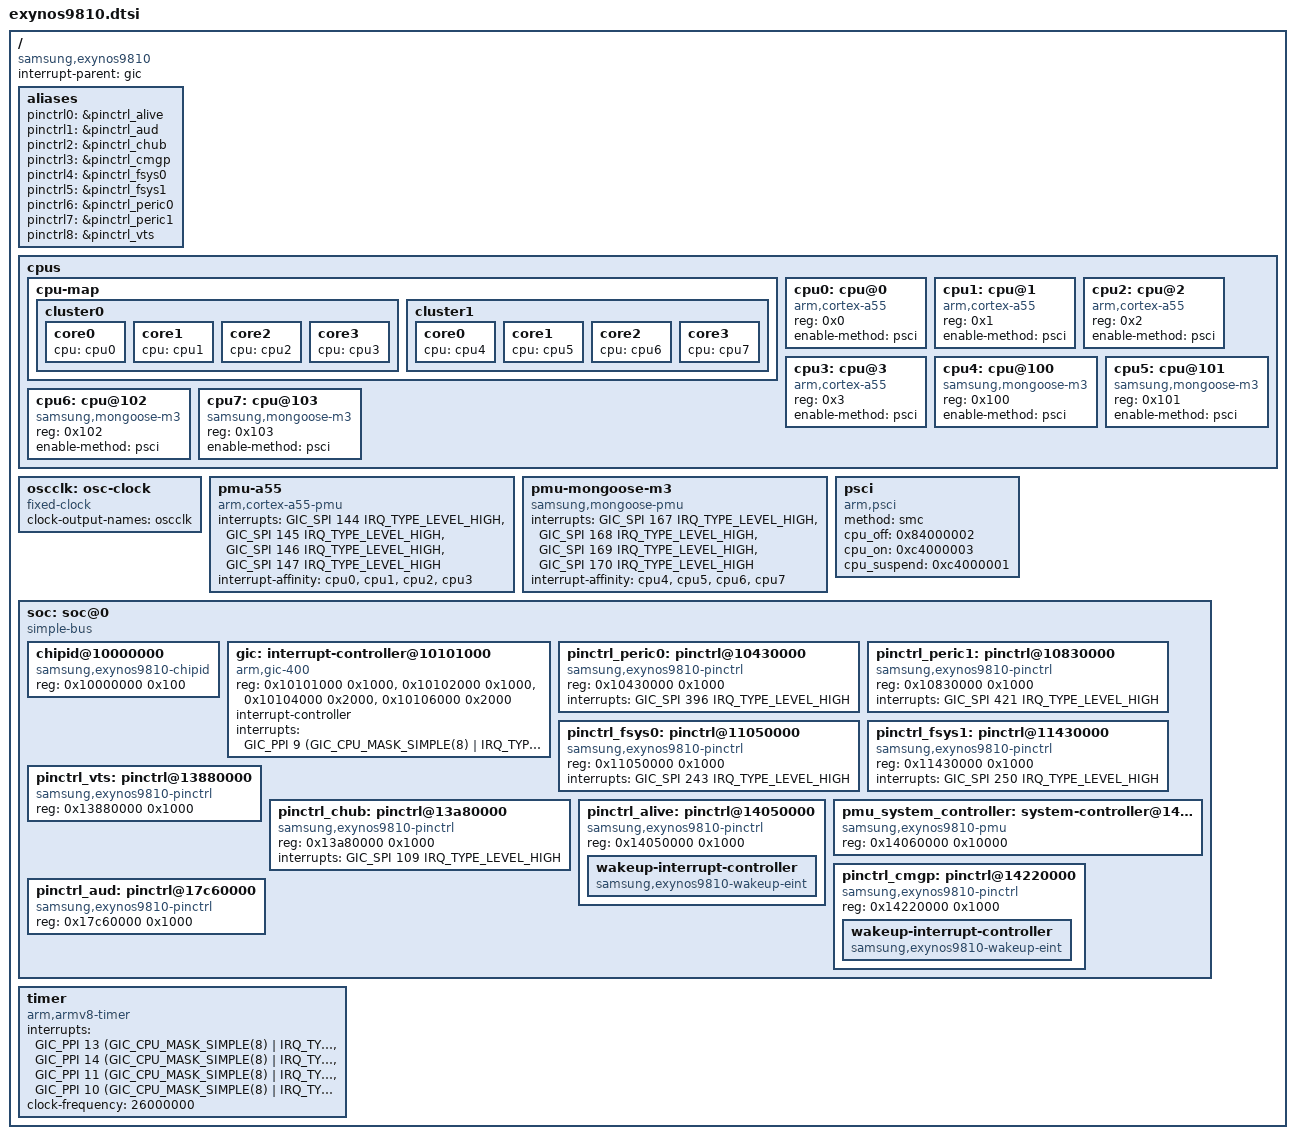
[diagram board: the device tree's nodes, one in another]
// SPDX-License-Identifier: GPL-2.0 OR BSD-3-Clause
/*
 * Samsung Exynos 9810 SoC device tree source
 *
 * Copyright (c) 2024 Markuss Broks <markuss.broks@gmail.com>
 * Copyright (c) 2024 Maksym Holovach <nergzd@nergzd723.xyz>
 */

#include <dt-bindings/interrupt-controller/arm-gic.h>

/ {
	compatible = "samsung,exynos9810";
	#address-cells = <2>;
	#size-cells = <1>;

	interrupt-parent = <&gic>;

	aliases {
		pinctrl0 = &pinctrl_alive;
		pinctrl1 = &pinctrl_aud;
		pinctrl2 = &pinctrl_chub;
		pinctrl3 = &pinctrl_cmgp;
		pinctrl4 = &pinctrl_fsys0;
		pinctrl5 = &pinctrl_fsys1;
		pinctrl6 = &pinctrl_peric0;
		pinctrl7 = &pinctrl_peric1;
		pinctrl8 = &pinctrl_vts;
	};

	cpus {
		#address-cells = <1>;
		#size-cells = <0>;

		cpu-map {
			cluster0 {
				core0 {
					cpu = <&cpu0>;
				};
				core1 {
					cpu = <&cpu1>;
				};
				core2 {
					cpu = <&cpu2>;
				};
				core3 {
					cpu = <&cpu3>;
				};
			};

			cluster1 {
				core0 {
					cpu = <&cpu4>;
				};
				core1 {
					cpu = <&cpu5>;
				};
				core2 {
					cpu = <&cpu6>;
				};
				core3 {
					cpu = <&cpu7>;
				};
			};
		};

		cpu0: cpu@0 {
			device_type = "cpu";
			compatible = "arm,cortex-a55";
			reg = <0x0>;
			enable-method = "psci";
		};

		cpu1: cpu@1 {
			device_type = "cpu";
			compatible = "arm,cortex-a55";
			reg = <0x1>;
			enable-method = "psci";
		};

		cpu2: cpu@2 {
			device_type = "cpu";
			compatible = "arm,cortex-a55";
			reg = <0x2>;
			enable-method = "psci";
		};

		cpu3: cpu@3 {
			device_type = "cpu";
			compatible = "arm,cortex-a55";
			reg = <0x3>;
			enable-method = "psci";
		};

		cpu4: cpu@100 {
			device_type = "cpu";
			compatible = "samsung,mongoose-m3";
			reg = <0x100>;
			enable-method = "psci";
		};

		cpu5: cpu@101 {
			device_type = "cpu";
			compatible = "samsung,mongoose-m3";
			reg = <0x101>;
			enable-method = "psci";
		};

		cpu6: cpu@102 {
			device_type = "cpu";
			compatible = "samsung,mongoose-m3";
			reg = <0x102>;
			enable-method = "psci";
		};

		cpu7: cpu@103 {
			device_type = "cpu";
			compatible = "samsung,mongoose-m3";
			reg = <0x103>;
			enable-method = "psci";
		};
	};

	oscclk: osc-clock {
		compatible = "fixed-clock";
		#clock-cells = <0>;
		clock-output-names = "oscclk";
	};

	pmu-a55 {
		compatible = "arm,cortex-a55-pmu";
		interrupts = <GIC_SPI 144 IRQ_TYPE_LEVEL_HIGH>,
			     <GIC_SPI 145 IRQ_TYPE_LEVEL_HIGH>,
			     <GIC_SPI 146 IRQ_TYPE_LEVEL_HIGH>,
			     <GIC_SPI 147 IRQ_TYPE_LEVEL_HIGH>;
		interrupt-affinity = <&cpu0>,
				     <&cpu1>,
				     <&cpu2>,
				     <&cpu3>;
	};

	pmu-mongoose-m3 {
		compatible = "samsung,mongoose-pmu";
		interrupts = <GIC_SPI 167 IRQ_TYPE_LEVEL_HIGH>,
			     <GIC_SPI 168 IRQ_TYPE_LEVEL_HIGH>,
			     <GIC_SPI 169 IRQ_TYPE_LEVEL_HIGH>,
			     <GIC_SPI 170 IRQ_TYPE_LEVEL_HIGH>;
		interrupt-affinity = <&cpu4>,
				     <&cpu5>,
				     <&cpu6>,
				     <&cpu7>;
	};

	psci {
		compatible = "arm,psci";
		method = "smc";
		cpu_off = <0x84000002>;
		cpu_on = <0xc4000003>;
		cpu_suspend = <0xc4000001>;
	};

	soc: soc@0 {
		compatible = "simple-bus";
		ranges = <0x0 0x0 0x0 0x20000000>;

		#address-cells = <1>;
		#size-cells = <1>;

		chipid@10000000 {
			compatible = "samsung,exynos9810-chipid",
				     "samsung,exynos850-chipid";
			reg = <0x10000000 0x100>;
		};

		gic: interrupt-controller@10101000 {
			compatible = "arm,gic-400";
			reg = <0x10101000 0x1000>,
			      <0x10102000 0x1000>,
			      <0x10104000 0x2000>,
			      <0x10106000 0x2000>;
			#interrupt-cells = <3>;
			interrupt-controller;
			interrupts = <GIC_PPI 9 (GIC_CPU_MASK_SIMPLE(8) |
						 IRQ_TYPE_LEVEL_HIGH)>;
			#address-cells = <0>;
			#size-cells = <1>;
		};

		pinctrl_peric0: pinctrl@10430000 {
			compatible = "samsung,exynos9810-pinctrl";
			reg = <0x10430000 0x1000>;
			interrupts = <GIC_SPI 396 IRQ_TYPE_LEVEL_HIGH>;
		};

		pinctrl_peric1: pinctrl@10830000 {
			compatible = "samsung,exynos9810-pinctrl";
			reg = <0x10830000 0x1000>;
			interrupts = <GIC_SPI 421 IRQ_TYPE_LEVEL_HIGH>;
		};

		pinctrl_fsys0: pinctrl@11050000 {
			compatible = "samsung,exynos9810-pinctrl";
			reg = <0x11050000 0x1000>;
			interrupts = <GIC_SPI 243 IRQ_TYPE_LEVEL_HIGH>;
		};

		pinctrl_fsys1: pinctrl@11430000 {
			compatible = "samsung,exynos9810-pinctrl";
			reg = <0x11430000 0x1000>;
			interrupts = <GIC_SPI 250 IRQ_TYPE_LEVEL_HIGH>;
		};

		pinctrl_vts: pinctrl@13880000 {
			compatible = "samsung,exynos9810-pinctrl";
			reg = <0x13880000 0x1000>;
		};

		pinctrl_chub: pinctrl@13a80000 {
			compatible = "samsung,exynos9810-pinctrl";
			reg = <0x13a80000 0x1000>;
			interrupts = <GIC_SPI 109 IRQ_TYPE_LEVEL_HIGH>;
		};

		pinctrl_alive: pinctrl@14050000 {
			compatible = "samsung,exynos9810-pinctrl";
			reg = <0x14050000 0x1000>;

			wakeup-interrupt-controller {
				compatible = "samsung,exynos9810-wakeup-eint",
					     "samsung,exynos850-wakeup-eint",
					     "samsung,exynos7-wakeup-eint";
			};
		};

		pmu_system_controller: system-controller@14060000 {
			compatible = "samsung,exynos9810-pmu",
				     "samsung,exynos7-pmu", "syscon";
			reg = <0x14060000 0x10000>;
		};

		pinctrl_cmgp: pinctrl@14220000 {
			compatible = "samsung,exynos9810-pinctrl";
			reg = <0x14220000 0x1000>;

			wakeup-interrupt-controller {
				compatible = "samsung,exynos9810-wakeup-eint",
					     "samsung,exynos850-wakeup-eint",
					     "samsung,exynos7-wakeup-eint";
			};
		};

		pinctrl_aud: pinctrl@17c60000 {
			compatible = "samsung,exynos9810-pinctrl";
			reg = <0x17c60000 0x1000>;
		};
	};

	timer {
		compatible = "arm,armv8-timer";
		/* Hypervisor Virtual Timer interrupt is not wired to GIC */
		interrupts = <GIC_PPI 13 (GIC_CPU_MASK_SIMPLE(8) | IRQ_TYPE_LEVEL_LOW)>,
			     <GIC_PPI 14 (GIC_CPU_MASK_SIMPLE(8) | IRQ_TYPE_LEVEL_LOW)>,
			     <GIC_PPI 11 (GIC_CPU_MASK_SIMPLE(8) | IRQ_TYPE_LEVEL_LOW)>,
			     <GIC_PPI 10 (GIC_CPU_MASK_SIMPLE(8) | IRQ_TYPE_LEVEL_LOW)>;
		/*
		 * Non-updatable, broken stock Samsung bootloader does not
		 * configure CNTFRQ_EL0
		 */
		clock-frequency = <26000000>;
	};
};

#include "exynos9810-pinctrl.dtsi"
#include "arm/samsung/exynos-syscon-restart.dtsi"
